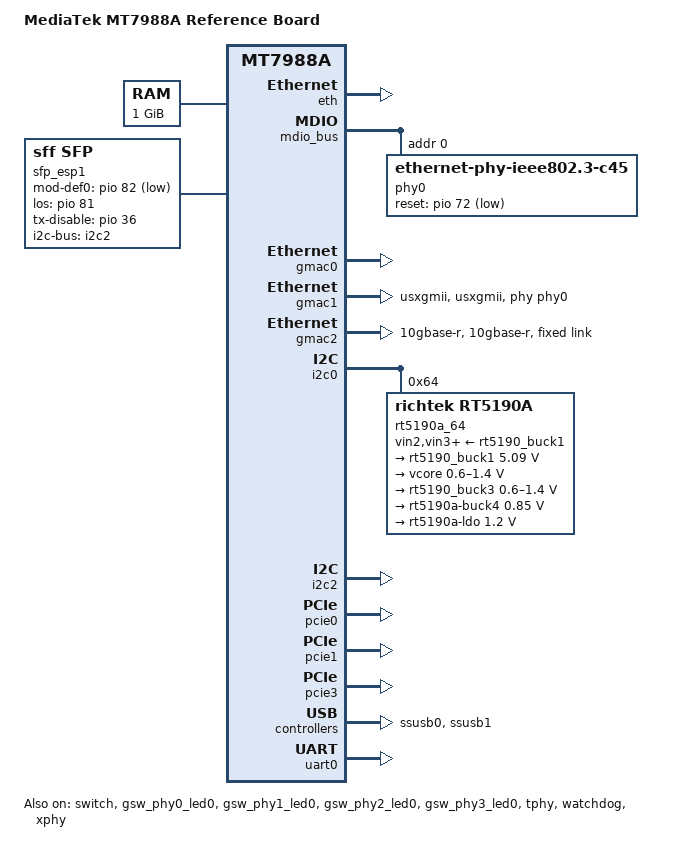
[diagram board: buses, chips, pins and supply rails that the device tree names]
// SPDX-License-Identifier: (GPL-2.0 OR MIT)
/*
 * Copyright (C) 2022 MediaTek Inc.
 * Author: Sam.Shih <sam.shih@mediatek.com>
 */

/dts-v1/;
#include "mt7988a.dtsi"
#include <dt-bindings/pinctrl/mt65xx.h>
#include <dt-bindings/leds/common.h>
#include <dt-bindings/gpio/gpio.h>
#include <dt-bindings/regulator/richtek,rt5190a-regulator.h>

/ {
	model = "MediaTek MT7988A Reference Board";
	compatible = "mediatek,mt7988a-rfb",
		     "mediatek,mt7988a";

	chosen {
		bootargs = "console=ttyS0,115200n1 loglevel=6  \
			    earlycon=uart8250,mmio32,0x11000000 \
			    pci=pcie_bus_perf ubi.block=0,firmware root=/dev/fit0 \
			    rootwait";
	};

	memory {
		reg = <0 0x40000000 0 0x40000000>;
	};

	sfp_esp1: sfp@1 {
		compatible = "sff,sfp";
		i2c-bus = <&i2c2>;
		mod-def0-gpios = <&pio 82 GPIO_ACTIVE_LOW>;
		los-gpios = <&pio 81 GPIO_ACTIVE_HIGH>;
		tx-disable-gpios = <&pio 36 GPIO_ACTIVE_HIGH>;
		maximum-power-milliwatt = <3000>;
	};
};

&eth {
	pinctrl-0 = <&mdio0_pins>;
	pinctrl-names = "default";

	mux: mux-bus {
		mux1: ethernet-mux@1 {
			compatible = "mediatek,eth-mux";
			reg = <1>;

			chan-sel-gpios = <&pio 30 GPIO_ACTIVE_HIGH>;
			mod-def0-gpios = <&pio 82 GPIO_ACTIVE_LOW>;

			channel0: channel@0 {
				reg = <0>;
				phy-mode = "usxgmii";
				phy-connection-type = "usxgmii";
				phy-handle = <&phy0>;
			};

			channel1: channel@1 {
				reg = <1>;
				phy-mode = "10gbase-r";
				phy-connection-type = "10gbase-r";
				managed = "in-band-status";
				sfp = <&sfp_esp1>;
			};
		};
	};
};

&mdio_bus {
	/* external Aquantia AQR113C */
	phy0: ethernet-phy@0 {
		reg = <0>;
		compatible = "ethernet-phy-ieee802.3-c45";
		firmware-name = "Rhe-05.06-Candidate9-AQR_Mediatek_23B_P5_ID45824_LCLVER1.cld";
		reset-gpios = <&pio 72 GPIO_ACTIVE_LOW>;
		reset-assert-us = <100000>;
		reset-deassert-us = <221000>;
	};
};

&gmac0 {
	status = "okay";
};

&gmac1 {
	phy-mode = "usxgmii";
	phy-connection-type = "usxgmii";
	phy = <&phy0>;
	status = "okay";
};

&gmac2 {
	phy-mode = "10gbase-r";
	phy-connection-type = "10gbase-r";
	status = "okay";

	fixed-link {
		speed = <10000>;
		full-duplex;
		pause;
	};
};

&cpu0 {
	proc-supply = <&rt5190_buck3>;
};

&cpu1 {
	proc-supply = <&rt5190_buck3>;
};

&cpu2 {
	proc-supply = <&rt5190_buck3>;
};

&cpu3 {
	proc-supply = <&rt5190_buck3>;
};

&cci {
	proc-supply = <&rt5190_buck3>;
};

&eth {
	status = "okay";
};

&switch {
	status = "okay";
};

&gsw_phy0 {
	pinctrl-names = "gbe-led";
	pinctrl-0 = <&gbe0_led0_pins>;
};

&gsw_phy0_led0 {
	status = "okay";
	color = <LED_COLOR_ID_GREEN>;
};

&gsw_phy1 {
	pinctrl-names = "gbe-led";
	pinctrl-0 = <&gbe1_led0_pins>;
};

&gsw_phy1_led0 {
	status = "okay";
	color = <LED_COLOR_ID_GREEN>;
};

&gsw_phy2 {
	pinctrl-names = "gbe-led";
	pinctrl-0 = <&gbe2_led0_pins>;
};

&gsw_phy2_led0 {
	status = "okay";
	color = <LED_COLOR_ID_GREEN>;
};

&gsw_phy3 {
	pinctrl-names = "gbe-led";
	pinctrl-0 = <&gbe3_led0_pins>;
};

&gsw_phy3_led0 {
	status = "okay";
	color = <LED_COLOR_ID_GREEN>;
};

&i2c0 {
	pinctrl-names = "default";
	pinctrl-0 = <&i2c0_pins>;
	status = "okay";

	rt5190a_64: rt5190a@64 {
		compatible = "richtek,rt5190a";
		reg = <0x64>;
		/*interrupts-extended = <&gpio26 0 IRQ_TYPE_LEVEL_LOW>;*/
		vin2-supply = <&rt5190_buck1>;
		vin3-supply = <&rt5190_buck1>;
		vin4-supply = <&rt5190_buck1>;

		regulators {
			rt5190_buck1: buck1 {
				regulator-name = "rt5190a-buck1";
				regulator-min-microvolt = <5090000>;
				regulator-max-microvolt = <5090000>;
				regulator-allowed-modes =
				<RT5190A_OPMODE_AUTO RT5190A_OPMODE_FPWM>;
				regulator-boot-on;
				regulator-always-on;
			};
			buck2 {
				regulator-name = "vcore";
				regulator-min-microvolt = <600000>;
				regulator-max-microvolt = <1400000>;
				regulator-boot-on;
				regulator-always-on;
			};
			rt5190_buck3: buck3 {
				regulator-name = "vproc";
				regulator-min-microvolt = <600000>;
				regulator-max-microvolt = <1400000>;
				regulator-boot-on;
			};
			buck4 {
				regulator-name = "rt5190a-buck4";
				regulator-min-microvolt = <850000>;
				regulator-max-microvolt = <850000>;
				regulator-allowed-modes =
				<RT5190A_OPMODE_AUTO RT5190A_OPMODE_FPWM>;
				regulator-boot-on;
				regulator-always-on;
			};
			ldo {
				regulator-name = "rt5190a-ldo";
				regulator-min-microvolt = <1200000>;
				regulator-max-microvolt = <1200000>;
				regulator-boot-on;
				regulator-always-on;
			};
		};
	};
};

&i2c2 {
	pinctrl-names = "default";
	pinctrl-0 = <&i2c2_0_pins>;
	status = "okay";
};

&pcie0 {
	status = "okay";
};

&pcie1 {
	status = "okay";
};

&pcie2 {
	status = "disabled";
};

&pcie3 {
	status = "okay";
};

&ssusb0 {
	status = "okay";
};

&ssusb1 {
	status = "okay";
};

&tphy {
	status = "okay";
};

&uart0 {
	status = "okay";
};

&watchdog {
	status = "okay";
};

&xphy {
	status = "okay";
};
